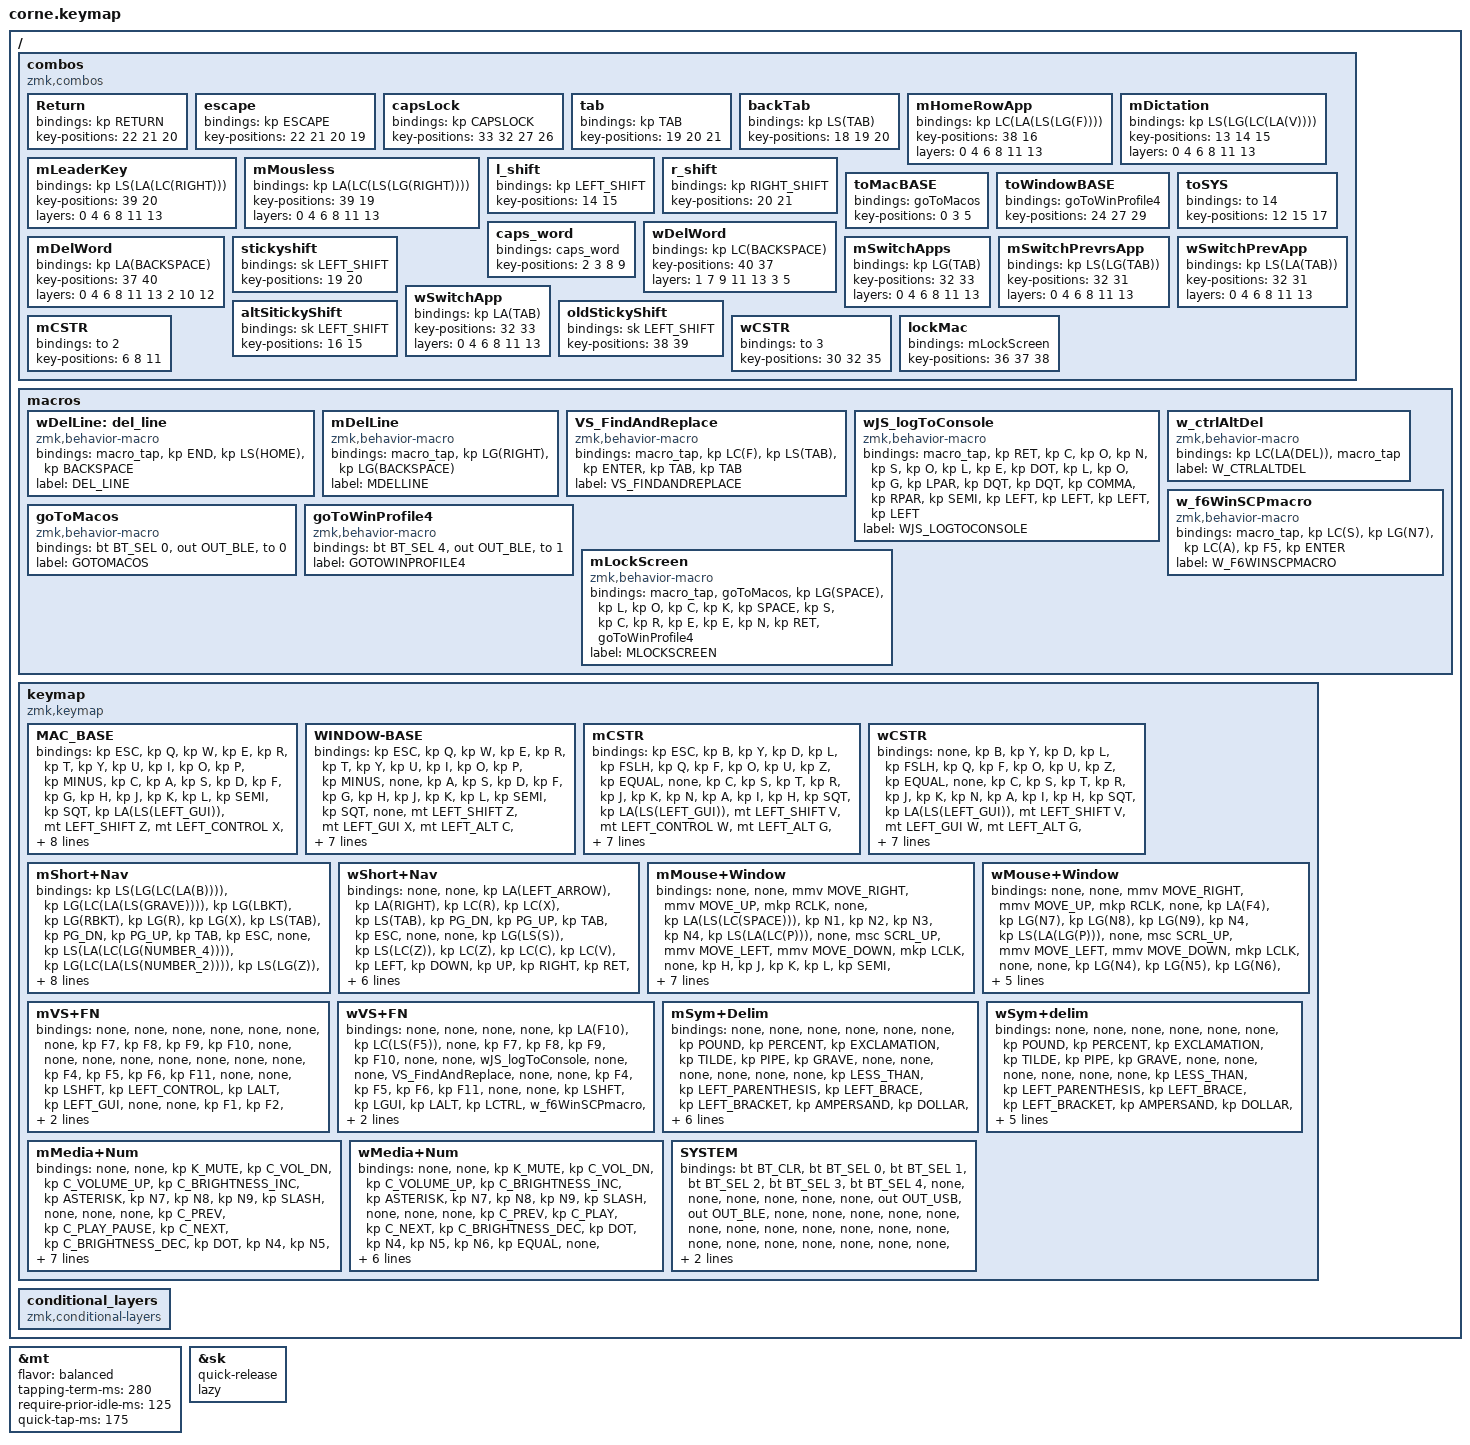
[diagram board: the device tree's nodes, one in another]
/*
 * Copyright (c) 2020 The ZMK Contributors
 *
 * SPDX-License-Identifier: MIT
 */

#include <behaviors.dtsi>
#include <dt-bindings/zmk/bt.h>
#include <dt-bindings/zmk/keys.h>
#include <dt-bindings/zmk/outputs.h>
#include <dt-bindings/zmk/pointing.h>

&mt {
    flavor = "balanced";
    tapping-term-ms = <280>;
    require-prior-idle-ms = <125>;
    quick-tap-ms = <175>;
};

&sk {
    quick-release;
    lazy;
};

/ {
    combos {
        compatible = "zmk,combos";

        Return {
            bindings = <&kp RETURN>;
            key-positions = <22 21 20>;
        };

        escape {
            bindings = <&kp ESCAPE>;
            key-positions = <22 21 20 19>;
        };

        capsLock {
            bindings = <&kp CAPSLOCK>;
            key-positions = <33 32 27 26>;
        };

        tab {
            bindings = <&kp TAB>;
            key-positions = <19 20 21>;
        };

        backTab {
            bindings = <&kp LS(TAB)>;
            key-positions = <18 19 20>;
        };

        mHomeRowApp {
            bindings = <&kp LC(LA(LS(LG(F))))>;
            key-positions = <38 16>;
            layers = <0 4 6 8 11 13>;
        };

        mDictation {
            bindings = <&kp LS(LG(LC(LA(V))))>;
            key-positions = <13 14 15>;
            layers = <0 4 6 8 11 13>;
        };

        mLeaderKey {
            bindings = <&kp LS(LA(LC(RIGHT)))>;
            key-positions = <39 20>;
            layers = <0 4 6 8 11 13>;
        };

        mMousless {
            bindings = <&kp LA(LC(LS(LG(RIGHT))))>;
            key-positions = <39 19>;
            layers = <0 4 6 8 11 13>;
        };

        l_shift {
            bindings = <&kp LEFT_SHIFT>;
            key-positions = <14 15>;
        };

        r_shift {
            bindings = <&kp RIGHT_SHIFT>;
            key-positions = <20 21>;
        };

        toMacBASE {
            bindings = <&goToMacos>;
            key-positions = <0 3 5>;
        };

        toWindowBASE {
            bindings = <&goToWinProfile4>;
            key-positions = <24 27 29>;
        };

        toSYS {
            bindings = <&to 14>;
            key-positions = <12 15 17>;
        };

        caps_word {
            bindings = <&caps_word>;
            key-positions = <2 3 8 9>;
        };

        mDelWord {
            bindings = <&kp LA(BACKSPACE)>;
            key-positions = <37 40>;
            layers = <0 4 6 8 11 13 2 10 12>;
        };

        wDelWord {
            bindings = <&kp LC(BACKSPACE)>;
            key-positions = <40 37>;
            layers = <1 7 9 11 13 3 5>;
        };

        stickyshift {
            bindings = <&sk LEFT_SHIFT>;
            key-positions = <19 20>;
        };

        mSwitchApps {
            bindings = <&kp LG(TAB)>;
            key-positions = <32 33>;
            layers = <0 4 6 8 11 13>;
        };

        mSwitchPrevrsApp {
            bindings = <&kp LS(LG(TAB))>;
            key-positions = <32 31>;
            layers = <0 4 6 8 11 13>;
        };

        wSwitchPrevApp {
            bindings = <&kp LS(LA(TAB))>;
            key-positions = <32 31>;
            layers = <0 4 6 8 11 13>;
        };

        wSwitchApp {
            bindings = <&kp LA(TAB)>;
            key-positions = <32 33>;
            layers = <0 4 6 8 11 13>;
        };

        altSitickyShift {
            bindings = <&sk LEFT_SHIFT>;
            key-positions = <16 15>;
        };

        oldStickyShift {
            bindings = <&sk LEFT_SHIFT>;
            key-positions = <38 39>;
        };

        mCSTR {
            bindings = <&to 2>;
            key-positions = <6 8 11>;
        };

        wCSTR {
            bindings = <&to 3>;
            key-positions = <30 32 35>;
        };

        lockMac {
            bindings = <&mLockScreen>;
            key-positions = <36 37 38>;
        };
    };

    macros {
        wDelLine: del_line {
            compatible = "zmk,behavior-macro";
            #binding-cells = <0>;
            bindings = <&macro_tap>, <&kp END &kp LS(HOME) &kp BACKSPACE>;

            label = "DEL_LINE";
        };

        mDelLine: mDelLine {
            compatible = "zmk,behavior-macro";
            #binding-cells = <0>;
            bindings = <&macro_tap>, <&kp LG(RIGHT) &kp LG(BACKSPACE)>;

            label = "MDELLINE";
        };

        VS_FindAndReplace: VS_FindAndReplace {
            compatible = "zmk,behavior-macro";
            #binding-cells = <0>;
            bindings =
                <&macro_tap>,
                <&kp LC(F) &kp LS(TAB) &kp ENTER &kp TAB &kp TAB>;

            label = "VS_FINDANDREPLACE";
        };

        wJS_logToConsole: wJS_logToConsole {
            compatible = "zmk,behavior-macro";
            #binding-cells = <0>;
            bindings =
                <&macro_tap>,
                <&kp RET &kp C &kp O &kp N &kp S &kp O &kp L &kp E &kp DOT &kp L &kp O &kp G &kp LPAR &kp DQT &kp DQT &kp COMMA &kp RPAR &kp SEMI &kp LEFT &kp LEFT &kp LEFT &kp LEFT>;

            label = "WJS_LOGTOCONSOLE";
        };

        w_ctrlAltDel: w_ctrlAltDel {
            compatible = "zmk,behavior-macro";
            #binding-cells = <0>;
            bindings = <&kp LC(LA(DEL))>, <&macro_tap>;

            label = "W_CTRLALTDEL";
        };

        w_f6WinSCPmacro: w_f6WinSCPmacro {
            compatible = "zmk,behavior-macro";
            #binding-cells = <0>;
            bindings =
                <&macro_tap>,
                <&kp LC(S) &kp LG(N7) &kp LC(A) &kp F5 &kp ENTER>;

            label = "W_F6WINSCPMACRO";
        };

        goToMacos: goToMacos {
            compatible = "zmk,behavior-macro";
            #binding-cells = <0>;
            bindings = <&bt BT_SEL 0 &out OUT_BLE &to 0>;
            label = "GOTOMACOS";
        };

        goToWinProfile4: goToWinProfile4 {
            compatible = "zmk,behavior-macro";
            #binding-cells = <0>;
            bindings = <&bt BT_SEL 4 &out OUT_BLE &to 1>;
            label = "GOTOWINPROFILE4";
        };

        mLockScreen: mLockScreen {
            compatible = "zmk,behavior-macro";
            #binding-cells = <0>;
            bindings =
                <&macro_tap>,
                <&goToMacos &kp LG(SPACE) &kp L &kp O &kp C &kp K &kp SPACE &kp S &kp C &kp R &kp E &kp E &kp N &kp RET &goToWinProfile4>;

            label = "MLOCKSCREEN";
        };
    };

    keymap {
        compatible = "zmk,keymap";

        MAC_BASE {
            bindings = <
&kp ESC               &kp Q             &kp W               &kp E           &kp R           &kp T                             &kp Y                            &kp U            &kp I                &kp O                     &kp P                  &kp MINUS
&kp C                 &kp A             &kp S               &kp D           &kp F           &kp G                             &kp H                            &kp J            &kp K                &kp L                     &kp SEMI               &kp SQT
&kp LA(LS(LEFT_GUI))  &mt LEFT_SHIFT Z  &mt LEFT_CONTROL X  &mt LEFT_ALT C  &mt LEFT_GUI V  &mt LS(LA(LC(LG(LEFT_GUI)))) B    &mt LC(LA(LS(LG(RIGHT_GUI)))) N  &mt RIGHT_GUI M  &mt RIGHT_ALT COMMA  &mt RIGHT_CONTROL PERIOD  &mt RIGHT_SHIFT SLASH  &none
                                                            &lt 6 ESCAPE    &lt 12 TAB      &lt 4 E                           &kp SPACE                        &lt 10 BSPC      &lt 8 DELETE
            >;
        };

        WINDOW-BASE {
            bindings = <
&kp ESC  &kp Q             &kp W           &kp E           &kp R               &kp T                             &kp Y                            &kp U               &kp I                &kp O              &kp P                 &kp MINUS
&none    &kp A             &kp S           &kp D           &kp F               &kp G                             &kp H                            &kp J               &kp K                &kp L              &kp SEMI              &kp SQT
&none    &mt LEFT_SHIFT Z  &mt LEFT_GUI X  &mt LEFT_ALT C  &mt LEFT_CONTROL V  &mt LS(LA(LC(LG(LEFT_GUI)))) B    &mt RS(RA(RC(RG(RIGHT_GUI)))) N  &mt LEFT_CONTROL M  &mt RIGHT_ALT COMMA  &mt RIGHT_GUI DOT  &mt RIGHT_SHIFT FSLH  &none
                                           &lt 7 ESCAPE    &lt 13 TAB          &lt 5 E                           &kp SPACE                        &lt 11 BSPC         &lt 9 DELETE
            >;
        };

        mCSTR {
            bindings = <
&kp ESC               &kp B             &kp Y               &kp D           &kp L           &kp FSLH                                  &kp Q                                &kp F            &kp O                &kp U                     &kp Z              &kp EQUAL
&none                 &kp C             &kp S               &kp T           &kp R           &kp J                                     &kp K                                &kp N            &kp A                &kp I                     &kp H              &kp SQT
&kp LA(LS(LEFT_GUI))  &mt LEFT_SHIFT V  &mt LEFT_CONTROL W  &mt LEFT_ALT G  &mt LEFT_GUI M  &mt LS(LA(LC(LG(LEFT_GUI)))) SEMICOLON    &mt LC(LA(LS(LG(RIGHT_GUI)))) MINUS  &mt RIGHT_GUI P  &mt RIGHT_ALT COMMA  &mt RIGHT_CONTROL PERIOD  &mt RIGHT_SHIFT X  &none
                                                            &lt 6 ESCAPE    &lt 13 TAB      &lt 4 E                                   &kp SPACE                            &lt 11 BSPC      &lt 8 DELETE
            >;
        };

        wCSTR {
            bindings = <
&none                 &kp B             &kp Y           &kp D           &kp L               &kp FSLH                                  &kp Q                                &kp F                &kp O                &kp U                 &kp Z              &kp EQUAL
&none                 &kp C             &kp S           &kp T           &kp R               &kp J                                     &kp K                                &kp N                &kp A                &kp I                 &kp H              &kp SQT
&kp LA(LS(LEFT_GUI))  &mt LEFT_SHIFT V  &mt LEFT_GUI W  &mt LEFT_ALT G  &mt LEFT_CONTROL M  &mt LS(LA(LC(LG(LEFT_GUI)))) SEMICOLON    &mt LC(LA(LS(LG(RIGHT_GUI)))) MINUS  &mt RIGHT_CONTROL P  &mt RIGHT_ALT COMMA  &mt RIGHT_GUI PERIOD  &mt RIGHT_SHIFT X  &none
                                                        &lt 7 ESCAPE    &lt 13 TAB          &lt 6 E                                   &kp SPACE                            &lt 11 BSPC          &lt 9 DELETE
            >;
        };

        mShort+Nav {
            bindings = <
&kp LS(LG(LC(LA(B))))         &kp LG(LC(LA(LS(GRAVE))))     &kp LG(LBKT)      &kp LG(RBKT)  &kp LG(R)         &kp LG(X)                           &kp LS(TAB)   &kp PG_DN  &kp PG_UP  &kp TAB        &kp ESC  &none
&kp LS(LA(LC(LG(NUMBER_4))))  &kp LG(LC(LA(LS(NUMBER_2))))  &kp LS(LG(Z))     &kp LG(Z)     &kp LG(C)         &kp LG(V)                           &kp LEFT      &kp DOWN   &kp UP     &kp RIGHT      &kp RET  &none
&kp LA(LS(LEFT_COMMAND))      &kp RSHFT                     &kp LEFT_CONTROL  &kp LALT      &kp LEFT_COMMAND  &kp LS(LA(LC(LG(LEFT_COMMAND))))    &kp LG(LEFT)  &mDelLine  &none      &kp LG(RIGHT)  &none    &none
                                                                              &none         &none             &none                               &kp SPACE     &kp BSPC   &kp DEL
            >;
        };

        wShort+Nav {
            bindings = <
&none                     &none          &kp LA(LEFT_ARROW)  &kp LA(RIGHT)  &kp LC(R)         &kp LC(X)                           &kp LS(TAB)  &kp PG_DN  &kp PG_UP  &kp TAB    &kp ESC  &none
&none                     &kp LG(LS(S))  &kp LS(LC(Z))       &kp LC(Z)      &kp LC(C)         &kp LC(V)                           &kp LEFT     &kp DOWN   &kp UP     &kp RIGHT  &kp RET  &none
&kp LA(LS(LEFT_COMMAND))  &kp RSHFT      &kp LEFT_GUI        &kp LALT       &kp LEFT_CONTROL  &kp LS(LA(LC(LG(LEFT_COMMAND))))    &kp HOME     &wDelLine  &none      &kp END    &none    &none
                                                             &w_ctrlAltDel  &none             &none                               &kp SPACE    &kp BSPC   &kp DEL
            >;
        };

        mMouse+Window {
            bindings = <
&none  &none           &mmv MOVE_RIGHT  &mmv MOVE_UP     &mkp RCLK  &none    &kp LA(LS(LC(SPACE)))       &kp N1                 &kp N2                 &kp N3         &kp N4    &kp LS(LA(LC(P)))
&none  &msc SCRL_UP    &mmv MOVE_LEFT   &mmv MOVE_DOWN   &mkp LCLK  &none    &kp H                       &kp J                  &kp K                  &kp L          &kp SEMI  &kp SQT
&none  &msc SCRL_DOWN  &msc SCRL_LEFT   &msc SCRL_RIGHT  &mkp MCLK  &none    &kp LS(LA(LC(F)))           &kp LS(LA(LC(MINUS)))  &kp LA(LS(LC(EQUAL)))  &kp LG(LC(F))  &none     &kp LA(LS(LC(R)))
                                        &none            &none      &none    &kp LA(LS(LC(LEFT_SHIFT)))  &kp LA(LC(LEFT_GUI))   &none
            >;
        };

        wMouse+Window {
            bindings = <
&none      &none           &mmv MOVE_RIGHT  &mmv MOVE_UP     &mkp RCLK  &none    &kp LA(F4)  &kp LG(N7)  &kp LG(N8)  &kp LG(N9)  &kp N4    &kp LS(LA(LG(P)))
&none      &msc SCRL_UP    &mmv MOVE_LEFT   &mmv MOVE_DOWN   &mkp LCLK  &none    &none       &kp LG(N4)  &kp LG(N5)  &kp LG(N6)  &kp SEMI  &kp SQT
&kp LG(Z)  &msc SCRL_DOWN  &msc SCRL_LEFT   &msc SCRL_RIGHT  &mkp MCLK  &none    &none       &kp LG(N1)  &kp LG(N2)  &kp LG(N3)  &none     &none
                                            &none            &none      &none    &kp N0      &none       &none
            >;
        };

        mVS+FN {
            bindings = <
&none  &none      &none             &none     &none         &none    &none  &kp F7  &kp F8  &kp F9  &kp F10  &none
&none  &none      &none             &none     &none         &none    &none  &kp F4  &kp F5  &kp F6  &kp F11  &none
&none  &kp LSHFT  &kp LEFT_CONTROL  &kp LALT  &kp LEFT_GUI  &none    &none  &kp F1  &kp F2  &kp F3  &kp F12  &none
                                    &none     &none         &none    &none  &none   &none
            >;
        };

        wVS+FN {
            bindings = <
&none  &none              &none     &none     &kp LA(F10)         &kp LC(LS(F5))      &none  &kp F7  &kp F8  &kp F9  &kp F10  &none
&none  &wJS_logToConsole  &none     &none     &VS_FindAndReplace  &none               &none  &kp F4  &kp F5  &kp F6  &kp F11  &none
&none  &kp LSHFT          &kp LGUI  &kp LALT  &kp LCTRL           &w_f6WinSCPmacro    &none  &kp F1  &kp F2  &kp F3  &kp F12  &none
                                    &none     &none               &none               &none  &none   &none
            >;
        };

        mSym+Delim {
            bindings = <
&none  &none      &none             &none     &none         &none    &kp POUND         &kp PERCENT            &kp EXCLAMATION  &kp TILDE          &kp PIPE       &kp GRAVE
&none  &none      &none             &none     &none         &none    &kp LESS_THAN     &kp LEFT_PARENTHESIS   &kp LEFT_BRACE   &kp LEFT_BRACKET   &kp AMPERSAND  &kp DOLLAR
&none  &kp LSHFT  &kp LEFT_CONTROL  &kp LALT  &kp LEFT_GUI  &none    &kp GREATER_THAN  &kp RIGHT_PARENTHESIS  &kp RIGHT_BRACE  &kp RIGHT_BRACKET  &kp AT_SIGN    &kp NON_US_BACKSLASH
                                    &none     &none         &none    &none             &none                  &none
            >;
        };

        wSym+delim {
            bindings = <
&none  &none      &none     &none     &none      &none    &kp POUND         &kp PERCENT            &kp EXCLAMATION  &kp TILDE          &kp PIPE       &kp GRAVE
&none  &none      &none     &none     &none      &none    &kp LESS_THAN     &kp LEFT_PARENTHESIS   &kp LEFT_BRACE   &kp LEFT_BRACKET   &kp AMPERSAND  &kp DOLLAR
&none  &kp LSHFT  &kp LGUI  &kp LALT  &kp LCTRL  &none    &kp GREATER_THAN  &kp RIGHT_PARENTHESIS  &kp RIGHT_BRACE  &kp RIGHT_BRACKET  &kp AT_SIGN    &kp NON_US_BACKSLASH
                            &none     &none      &none    &none             &none                  &none
            >;
        };

        mMedia+Num {
            bindings = <
&none                 &none      &kp K_MUTE        &kp C_VOL_DN      &kp C_VOLUME_UP  &kp C_BRIGHTNESS_INC                          &kp ASTERISK  &kp N7     &kp N8    &kp N9  &kp SLASH  &none
&none                 &none      &kp C_PREV        &kp C_PLAY_PAUSE  &kp C_NEXT       &kp C_BRIGHTNESS_DEC                          &kp DOT       &kp N4     &kp N5    &kp N6  &kp EQUAL  &none
&kp LS(LA(LEFT_GUI))  &kp LSHFT  &kp LEFT_CONTROL  &kp LALT          &kp LEFT_GUI     &mt LC(LA(LS(LEFT_GUI))) C_BRIGHTNESS_AUTO    &kp PLUS      &kp N1     &kp N2    &kp N3  &kp MINUS  &none
                                                   &none             &none            &none                                         &kp N0        &kp SPACE  &kp BSPC
            >;
        };

        wMedia+Num {
            bindings = <
&none                 &none      &kp K_MUTE  &kp C_VOL_DN  &kp C_VOLUME_UP  &kp C_BRIGHTNESS_INC                          &kp ASTERISK  &kp N7     &kp N8    &kp N9  &kp SLASH  &none
&none                 &none      &kp C_PREV  &kp C_PLAY    &kp C_NEXT       &kp C_BRIGHTNESS_DEC                          &kp DOT       &kp N4     &kp N5    &kp N6  &kp EQUAL  &none
&kp LS(LA(LEFT_GUI))  &kp LSHFT  &kp LGUI    &kp LALT      &kp LCTRL        &mt LC(LA(LS(LEFT_GUI))) C_BRIGHTNESS_AUTO    &kp PLUS      &kp N1     &kp N2    &kp N3  &kp MINUS  &none
                                             &none         &none            &none                                         &kp N0        &kp SPACE  &kp BSPC
            >;
        };

        SYSTEM {
            bindings = <
&bt BT_CLR    &bt BT_SEL 0  &bt BT_SEL 1  &bt BT_SEL 2  &bt BT_SEL 3  &bt BT_SEL 4    &none  &none  &none  &none  &none  &none
&out OUT_USB  &out OUT_BLE  &none         &none         &none         &none           &none  &none  &none  &none  &none  &none
&none         &none         &none         &none         &none         &none           &none  &none  &none  &none  &none  &none
                                          &none         &none         &none           &none  &none  &none
            >;
        };
    };

    conditional_layers { compatible = "zmk,conditional-layers"; };
};
